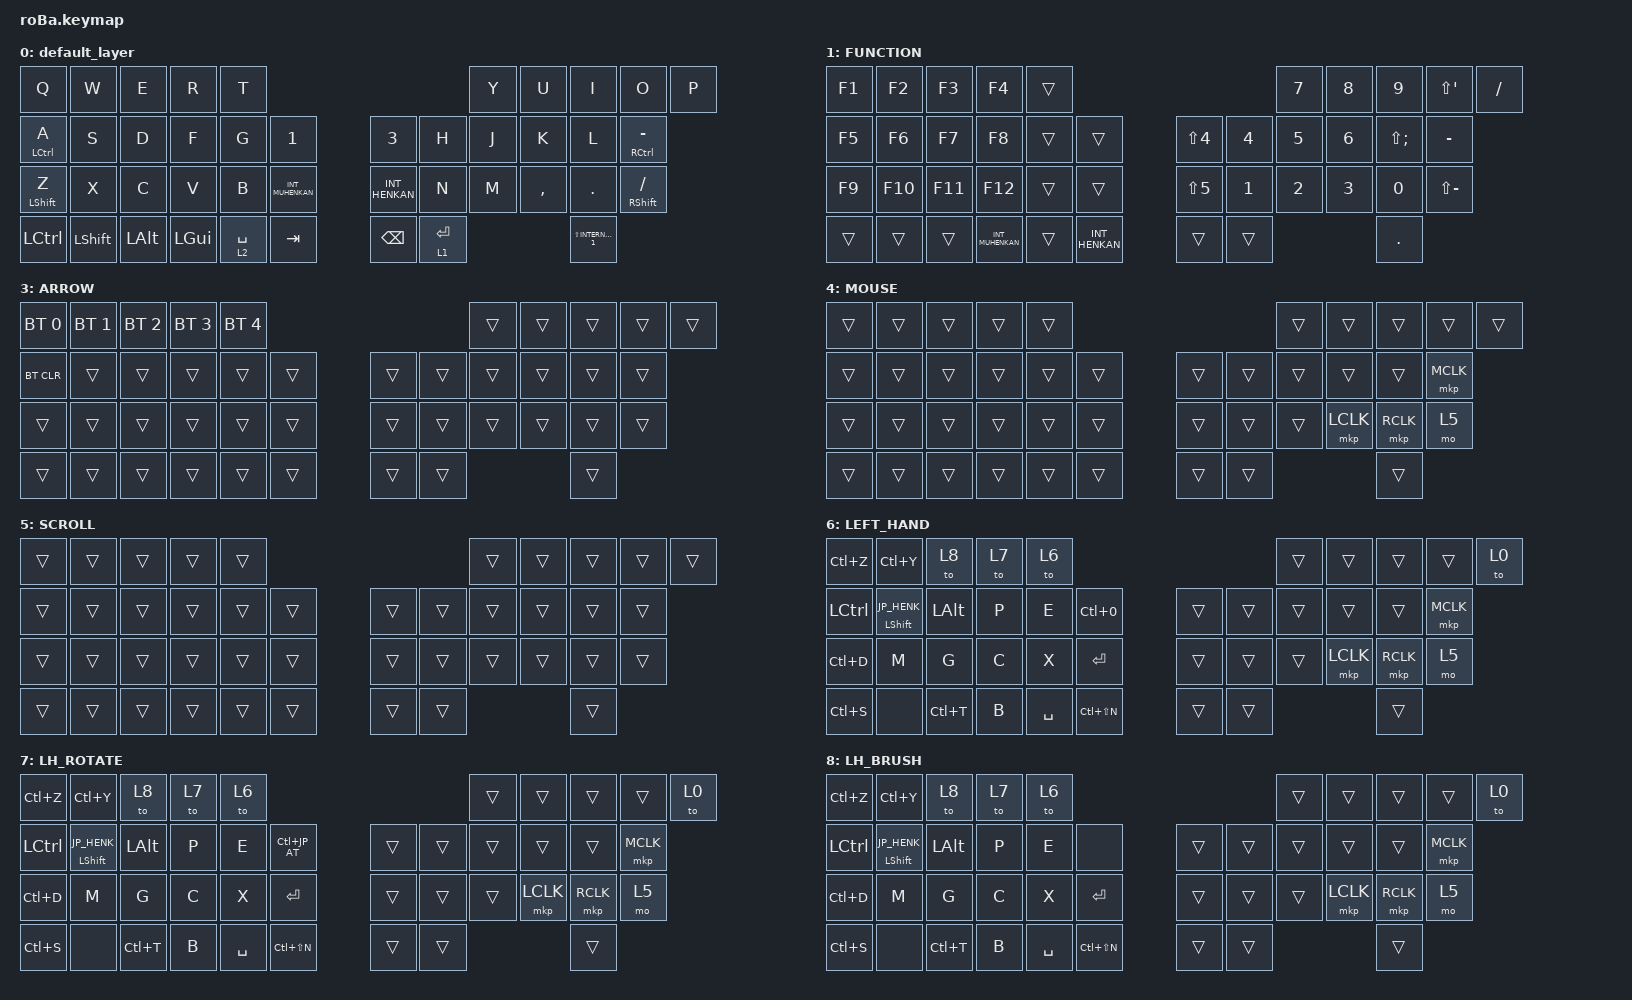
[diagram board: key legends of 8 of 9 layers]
#include <behaviors.dtsi>
#include <dt-bindings/zmk/bt.h>
#include <dt-bindings/zmk/keys.h>
#define ZMK_POINTING_DEFAULT_SCRL_VAL 80
#include <dt-bindings/zmk/pointing.h>
#include "keys_ja.h"

&mt {
    flavor = "balanced";
    quick-tap-ms = <0>;
};

/* ========================================================================== */
/* 1. 先にルートノード（/）を開いて、zip_temp_layer の中身をしっかり定義する   */
/* ========================================================================== */
/ {
    zip_temp_layer: zip_temp_layer {
        compatible = "zmk,input-processor-temp-layer";
        #input-processor-cells = <2>;
        require-prior-idle-ms = <0>;
    };
};

/* ========================================================================== */
/* 2. 定義が完了した後に、それらを使った設定（&）を記述する                  */
/* ========================================================================== */
&trackball { scroll-layers = <5>; };

&trackball_listener { input-processors = <&zip_temp_layer 4 10000>; };

&zip_temp_layer { excluded-positions = <21 31 32 33>; };

/* ========================================================================== */
/* 3. 残りの combos などの定義を続ける（ここもルートノードの中身です）        */
/* ========================================================================== */
/ {
    combos {
        compatible = "zmk,combos";
        /* 既存コンボは LEFT_HAND（Layer 6, 7, 8）では無効にする（修飾キー同時押しでの暴発防止） */
        tab {
            bindings = <&kp TAB>;
            key-positions = <11 12>;
            layers = <0 1 2 3 4 5>;
        };

        shift_tab {
            bindings = <&kp LS(TAB)>;
            key-positions = <12 13>;
            layers = <0 1 2 3 4 5>;
        };

        muhennkann {
            bindings = <&to_layer_0 INT_MUHENKAN>;
            key-positions = <11 10>;
            layers = <0 1 2 3 4 5>;
        };

        double_quotation {
            bindings = <&kp DOUBLE_QUOTES>;
            key-positions = <20 21>;
            layers = <0 1 2 3 4 5>;
        };

        eq {
            bindings = <&kp EQUAL>;
            key-positions = <24 25>;
            layers = <0 1 2 3 4 5>;
        };

        /* Space（38）+ 無変換（27）同時押しで LEFT_HAND（Layer 6）に入る
         * ※手のひら操作中の誤爆を防ぐため、解除は右手端（9番キー: P位置）で行います */
        left_hand_enter {
            bindings = <&tog 6>;
            key-positions = <27 38>;
            layers = <0 1 2 3 4 5>;
            require-prior-idle-ms = <150>;
        };
    };

    macros {
        to_layer_0: to_layer_0 {
            compatible = "zmk,behavior-macro-one-param";
            #binding-cells = <1>;
            bindings = <&to 0 &macro_param_1to1 &kp MACRO_PLACEHOLDER>;
            label = "TO_LAYER_0";
        };


    };

    behaviors {
        lt_to_layer_0: lt_to_layer_0 {
            compatible = "zmk,behavior-hold-tap";
            label = "LAYER_TAP_TO_0";
            bindings = <&mo>, <&to_layer_0>;

            #binding-cells = <2>;
            tapping-term-ms = <200>;
        };

        encoder_msc_down_up: encoder_msc_down_up {
            compatible = "zmk,behavior-sensor-rotate";
            label = "ENCODER_MSC_DOWN_UP";
            #sensor-binding-cells = <0>;
            bindings = <&msc SCRL_DOWN>, <&msc SCRL_UP>;
            tap-ms = <20>;
        };
    };

    conditional_layers {
        compatible = "zmk,conditional-layers";

        tri_layer {
            if-layers = <1 2>;
            then-layer = <3>;
        };
    };

    keymap {
        compatible = "zmk,keymap";

        default_layer {
            bindings = <
            &kp Q           &kp W         &kp E         &kp R        &kp T                                                     &kp Y   &kp U      &kp I    &kp O                    &kp P
      &mt LCTRL A           &kp S         &kp D         &kp F        &kp G  &kp NUMBER_1                   &kp NUMBER_3        &kp H   &kp J      &kp K    &kp L          &mt RCTRL MINUS
 &mt LEFT_SHIFT Z           &kp X         &kp C         &kp V        &kp B  &kp INT_MUHENKAN               &kp INT_HENKAN      &kp N   &kp M  &kp COMMA  &kp DOT          &mt RSHFT SLASH
        &kp LCTRL  &kp LEFT_SHIFT  &kp LEFT_ALT  &kp LEFT_GUI  &lt 2 SPACE       &kp TAB                  &kp BACKSPACE  &lt 1 ENTER                              &kp LS(INTERNATIONAL_1)
            >;

            sensor-bindings = <&encoder_msc_down_up>;
        };

        FUNCTION {
            bindings = <
 &kp F1   &kp F2   &kp F3   &kp F4  &trans                                            &kp NUMBER_7  &kp NUMBER_8  &kp NUMBER_9  &kp LS(SINGLE_QUOTE)      &kp SLASH
 &kp F5   &kp F6   &kp F7   &kp F8  &trans  &trans                  &kp LS(NUMBER_4)  &kp NUMBER_4  &kp NUMBER_5  &kp NUMBER_6     &kp LS(SEMICOLON)      &kp MINUS
 &kp F9  &kp F10  &kp F11  &kp F12  &trans  &trans                  &kp LS(NUMBER_5)  &kp NUMBER_1  &kp NUMBER_2  &kp NUMBER_3          &kp NUMBER_0  &kp LS(MINUS)
 &trans   &trans   &trans   &kp INT_MUHENKAN  &trans  &kp INT_HENKAN                            &trans        &trans                                                       &kp PERIOD
            >;
        };

        NUM {
            bindings = <
        &kp ESC    &kp UP_ARROW       &kp INSERT  &kp SCROLLLOCK    &kp C_PAUSE                                                &kp LS(NUMBER_1)  &kp LS(NUMBER_2)  &kp LS(RIGHT_BRACKET)  &kp LS(BACKSLASH)         &kp LS(NUMBER_3)
 &kp LEFT_ARROW  &kp DOWN_ARROW  &kp RIGHT_ARROW        &kp HOME      &kp PG_UP  &trans                  &kp LS(LEFT_BRACKET)  &kp LS(NUMBER_6)  &kp LS(NUMBER_7)      &kp RIGHT_BRACKET      &kp BACKSLASH  &kp LS(INTERNATIONAL_3)
      &kp GRAVE          &trans           &trans         &kp END  &kp PAGE_DOWN  &trans                      &kp LEFT_BRACKET     &kp SEMICOLON  &kp SINGLE_QUOTE       &kp LS(NUMBER_8)   &kp LS(NUMBER_9)      &kp INTERNATIONAL_3
      &kp GRAVE          &trans           &trans          &trans         &trans  &trans                            &kp DELETE            &trans                                                                        &kp LS(EQUAL)                                                                  &kp PIPE
            >;
        };

        ARROW {
            bindings = <
&bt BT_SEL 0  &bt BT_SEL 1  &bt BT_SEL 2  &bt BT_SEL 3  &bt BT_SEL 4                      &trans  &trans  &trans  &trans  &trans
&bt BT_CLR    &trans        &trans        &trans        &trans        &trans      &trans  &trans  &trans  &trans  &trans  &trans
&trans        &trans        &trans        &trans        &trans        &trans      &trans  &trans  &trans  &trans  &trans  &trans
&trans        &trans        &trans        &trans        &trans        &trans      &trans  &trans                          &trans
            >;

            sensor-bindings = <&inc_dec_kp LC(PAGE_UP) LC(PAGE_DOWN)>;
        };

        MOUSE {
            bindings = <
&trans  &trans  &trans  &trans  &trans                                  &trans  &trans     &trans     &trans  &trans
&trans  &trans  &trans  &trans  &trans  &trans                  &trans  &trans  &trans     &trans     &trans  &mkp MCLK
&trans  &trans  &trans  &trans  &trans  &trans                  &trans  &trans  &trans  &mkp LCLK  &mkp RCLK   &mo 5
&trans  &trans  &trans  &trans  &trans  &trans                  &trans  &trans                                &trans
            >;
        };

        SCROLL {
            bindings = <
&trans  &trans  &trans  &trans  &trans                      &trans  &trans  &trans  &trans  &trans
&trans  &trans  &trans  &trans  &trans  &trans      &trans  &trans  &trans  &trans  &trans  &trans
&trans  &trans  &trans  &trans  &trans  &trans      &trans  &trans  &trans  &trans  &trans  &trans
&trans  &trans  &trans  &trans  &trans  &trans      &trans  &trans                          &trans
            >;
        };

        /* ======================================================================
         * Layer 6: LEFT_HAND (CLIP STUDIO 左手デバイス / ズームモード)
         * - エンコーダー右回転: ズームイン LC(JP_PLUS)
         * - エンコーダー左回転: ズームアウト LC(JP_MINUS)
         * - エンコーダー押し込み(15): 全体表示リセット LC(NUMBER_0)
         * - 切替キー: 位置2=&to 8 (ブラシ), 位置3=&to 7 (回転), 位置4=&to 6 (ズーム)
         * - 解除: 右手 P位置 (キー9番) の &to 0
         * ====================================================================== */
        LEFT_HAND {
            bindings = <
&kp LC(Z)  &kp LC(Y)         &to 8             &to 7          &to 6                                                       &trans  &trans  &trans     &trans     &to 0
&kp LCTRL  &mt LSHFT JP_HENK &kp LALT          &kp P          &kp E          &kp LC(NUMBER_0)         &trans  &trans  &trans     &trans     &trans     &mkp MCLK
&kp LC(D)  &kp M             &kp G             &kp C          &kp X          &kp ENTER                &trans  &trans  &trans     &mkp LCLK  &mkp RCLK  &mo 5
&kp LC(S)  &none             &kp LC(T)         &kp B          &kp SPACE      &kp LC(LS(N))            &trans  &trans                                   &trans
            >;

            sensor-bindings = <&inc_dec_kp LC(JP_PLUS) LC(JP_MINUS)>;
        };

        /* ======================================================================
         * Layer 7: LH_ROTATE (CLIP STUDIO 左手デバイス / キャンバス回転モード)
         * - エンコーダー右回転: 右回転 JP_CARET (^)
         * - エンコーダー左回転: 左回転 JP_MINUS (-)
         * - エンコーダー押し込み(15): 表示位置・回転リセット LC(JP_AT) (Ctrl+@)
         * - 切替キー: 位置2=&to 8 (ブラシ), 位置3=&to 7 (回転), 位置4=&to 6 (ズーム)
         * - 解除: 右手 P位置 (キー9番) の &to 0
         * ====================================================================== */
        LH_ROTATE {
            bindings = <
&kp LC(Z)  &kp LC(Y)         &to 8             &to 7          &to 6                                                       &trans  &trans  &trans     &trans     &to 0
&kp LCTRL  &mt LSHFT JP_HENK &kp LALT          &kp P          &kp E          &kp LC(JP_AT)            &trans  &trans  &trans     &trans     &trans     &mkp MCLK
&kp LC(D)  &kp M             &kp G             &kp C          &kp X          &kp ENTER                &trans  &trans  &trans     &mkp LCLK  &mkp RCLK  &mo 5
&kp LC(S)  &none             &kp LC(T)         &kp B          &kp SPACE      &kp LC(LS(N))            &trans  &trans                                   &trans
            >;

            sensor-bindings = <&inc_dec_kp JP_CARET JP_MINUS>;
        };

        /* ======================================================================
         * Layer 8: LH_BRUSH (CLIP STUDIO 左手デバイス / ブラシサイズモード)
         * - エンコーダー右回転: ブラシ拡大 JP_RIGHT_BRACKET (])
         * - エンコーダー左回転: ブラシ縮小 JP_LEFT_BRACKET ([)
         * - エンコーダー押し込み(15): 無効 (&none)
         * - 切替キー: 位置2=&to 8 (ブラシ), 位置3=&to 7 (回転), 位置4=&to 6 (ズーム)
         * - 解除: 右手 P位置 (キー9番) の &to 0
         * ====================================================================== */
        LH_BRUSH {
            bindings = <
&kp LC(Z)  &kp LC(Y)         &to 8             &to 7          &to 6                                                       &trans  &trans  &trans     &trans     &to 0
&kp LCTRL  &mt LSHFT JP_HENK &kp LALT          &kp P          &kp E          &none                    &trans  &trans  &trans     &trans     &trans     &mkp MCLK
&kp LC(D)  &kp M             &kp G             &kp C          &kp X          &kp ENTER                &trans  &trans  &trans     &mkp LCLK  &mkp RCLK  &mo 5
&kp LC(S)  &none             &kp LC(T)         &kp B          &kp SPACE      &kp LC(LS(N))            &trans  &trans                                   &trans
            >;

            sensor-bindings = <&inc_dec_kp JP_RIGHT_BRACKET JP_LEFT_BRACKET>;
        };
    };
};
